# CC430F5123 register map
Registers are 16-bit, read-write, reset 0x0 unless marked. A register's access mark holds for its fields unless they carry their own. Offsets are from the block's base; [hi:lo] are bit positions; {n}, {i} and the like mark numbered series.

## Port_C
Base 0x00000000
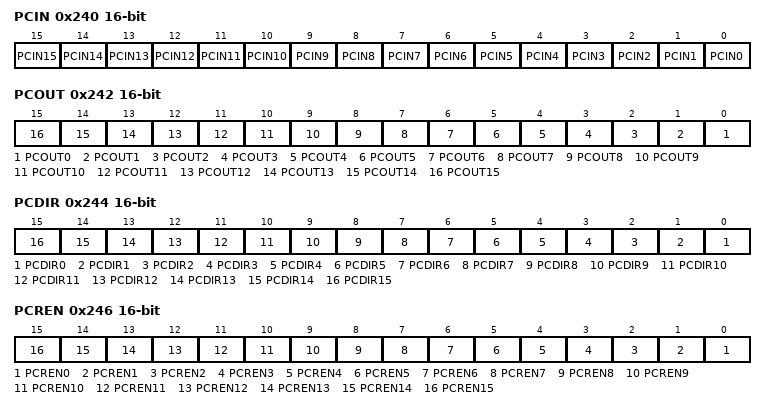
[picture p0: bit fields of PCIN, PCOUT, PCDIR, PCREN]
0x240 PCIN — Port C Input
  [n] PCIN{n} (n=0..15)
0x242 PCOUT — Port C Output
  [n] PCOUT{n} (n=0..15)
0x244 PCDIR — Port C Direction
  [n] PCDIR{n} (n=0..15)
0x246 PCREN — Port C Resistor Enable
  [n] PCREN{n} (n=0..15)
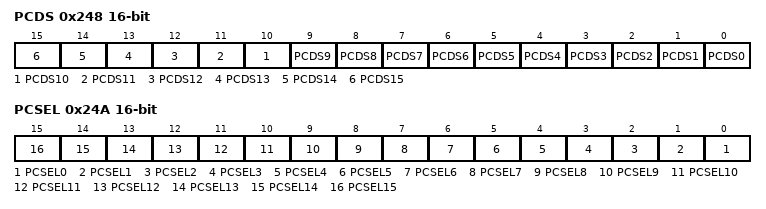
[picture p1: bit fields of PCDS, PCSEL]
0x248 PCDS — Port C Drive Strenght
  [n] PCDS{n} (n=0..15)
0x24A PCSEL — Port C Selection
  [n] PCSEL{n} (n=0..15)

## Port_5
Base 0x00000000
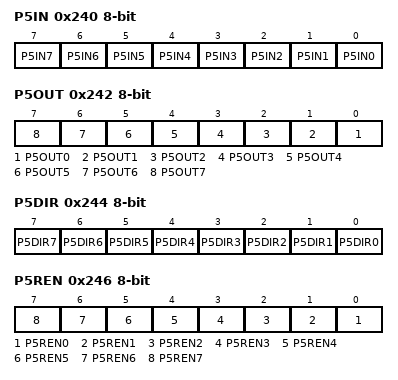
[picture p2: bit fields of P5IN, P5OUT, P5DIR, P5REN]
0x240 P5IN 8-bit — Port 5 Input
  [n] P5IN{n} (n=0..7)
0x242 P5OUT 8-bit — Port 5 Output
  [n] P5OUT{n} (n=0..7)
0x244 P5DIR 8-bit — Port 5 Direction
  [n] P5DIR{n} (n=0..7)
0x246 P5REN 8-bit — Port 5 Resistor Enable
  [n] P5REN{n} (n=0..7)
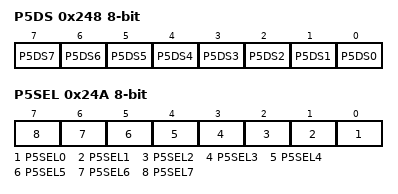
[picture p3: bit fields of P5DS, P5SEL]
0x248 P5DS 8-bit — Port 5 Drive Strenght
  [n] P5DS{n} (n=0..7)
0x24A P5SEL 8-bit — Port 5 Selection
  [n] P5SEL{n} (n=0..7)

## Port_J
Base 0x00000000
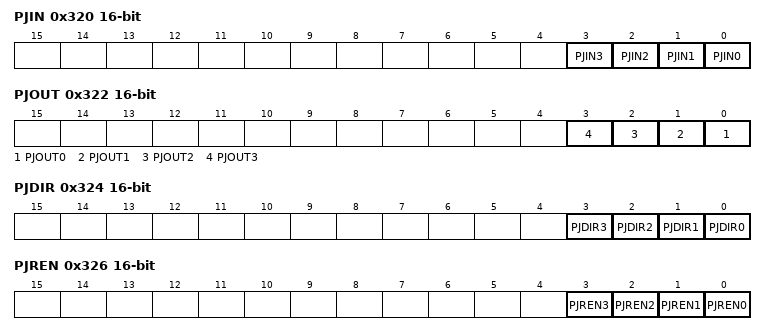
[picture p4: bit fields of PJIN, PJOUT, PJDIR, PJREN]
0x320 PJIN — Port J Input
  [n] PJIN{n} (n=0..3)
0x322 PJOUT — Port J Output
  [n] PJOUT{n} (n=0..3)
0x324 PJDIR — Port J Direction
  [n] PJDIR{n} (n=0..3)
0x326 PJREN — Port J Resistor Enable
  [n] PJREN{n} (n=0..3)
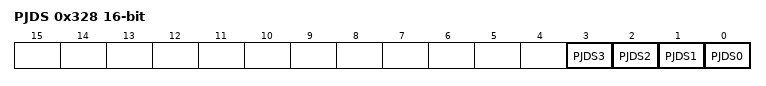
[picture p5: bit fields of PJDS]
0x328 PJDS — Port J Drive Strenght
  [n] PJDS{n} (n=0..3)

## Port_Mapping_Control
Base 0x00000000
0x1C0 PMAPKEYID — Port Mapping Key register
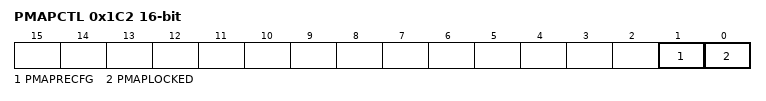
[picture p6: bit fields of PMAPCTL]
0x1C2 PMAPCTL — Port Mapping control register
  [1] PMAPRECFG — Port Mapping re-configuration control bit
  [0] PMAPLOCKED — Port Mapping Lock bit. Read only

## Port_Mapping_Port_1
Base 0x00000000
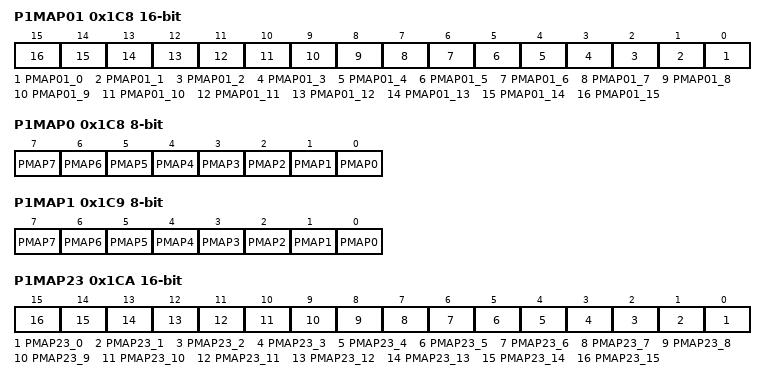
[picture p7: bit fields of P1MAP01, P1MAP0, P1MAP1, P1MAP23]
0x1C8 P1MAP01 — Port P1.0/1 mapping register
  [n] PMAP01_{n} (n=0..15)
0x1C8 P1MAP0 8-bit — Port P1.0 mapping register
  [n] PMAP{n} (n=0..7)
0x1C9 P1MAP1 8-bit — Port P1.1 mapping register
  [n] PMAP{n} (n=0..7)
0x1CA P1MAP23 — Port P1.2/3 mapping register
  [n] PMAP23_{n} (n=0..15)
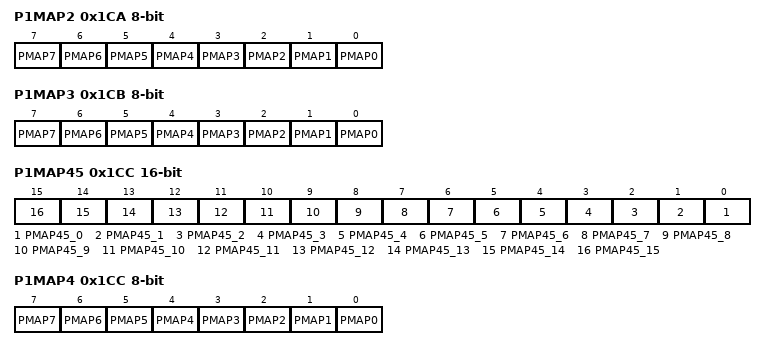
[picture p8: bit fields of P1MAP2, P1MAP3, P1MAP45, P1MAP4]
0x1CA P1MAP2 8-bit — Port P1.2 mapping register
  [n] PMAP{n} (n=0..7)
0x1CB P1MAP3 8-bit — Port P1.3 mapping register
  [n] PMAP{n} (n=0..7)
0x1CC P1MAP45 — Port P1.4/5 mapping register
  [n] PMAP45_{n} (n=0..15)
0x1CC P1MAP4 8-bit — Port P1.4 mapping register
  [n] PMAP{n} (n=0..7)
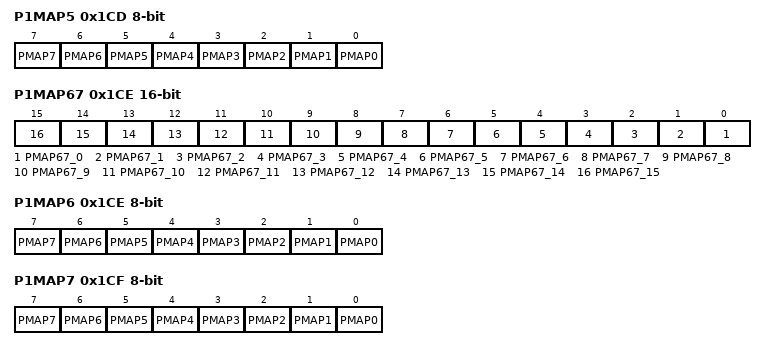
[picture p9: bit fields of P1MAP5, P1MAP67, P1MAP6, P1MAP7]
0x1CD P1MAP5 8-bit — Port P1.5 mapping register
  [n] PMAP{n} (n=0..7)
0x1CE P1MAP67 — Port P1.6/7 mapping register
  [n] PMAP67_{n} (n=0..15)
0x1CE P1MAP6 8-bit — Port P1.6 mapping register
  [n] PMAP{n} (n=0..7)
0x1CF P1MAP7 8-bit — Port P1.7 mapping register
  [n] PMAP{n} (n=0..7)

## Port_Mapping_Port_2
Base 0x00000000
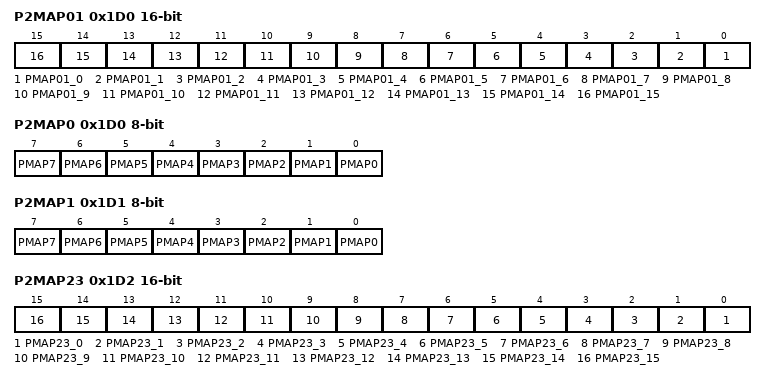
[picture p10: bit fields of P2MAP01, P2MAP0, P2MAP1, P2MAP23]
0x1D0 P2MAP01 — Port P2.0/1 mapping register
  [n] PMAP01_{n} (n=0..15)
0x1D0 P2MAP0 8-bit — Port P2.0 mapping register
  [n] PMAP{n} (n=0..7)
0x1D1 P2MAP1 8-bit — Port P2.1 mapping register
  [n] PMAP{n} (n=0..7)
0x1D2 P2MAP23 — Port P2.2/3 mapping register
  [n] PMAP23_{n} (n=0..15)
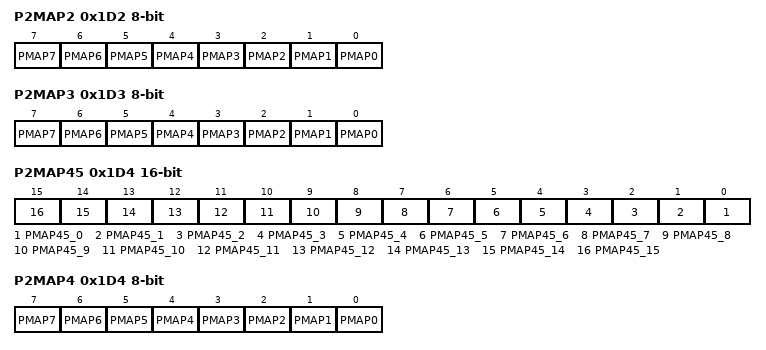
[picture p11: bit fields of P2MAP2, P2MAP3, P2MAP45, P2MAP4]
0x1D2 P2MAP2 8-bit — Port P2.2 mapping register
  [n] PMAP{n} (n=0..7)
0x1D3 P2MAP3 8-bit — Port P2.3 mapping register
  [n] PMAP{n} (n=0..7)
0x1D4 P2MAP45 — Port P2.4/5 mapping register
  [n] PMAP45_{n} (n=0..15)
0x1D4 P2MAP4 8-bit — Port P2.4 mapping register
  [n] PMAP{n} (n=0..7)
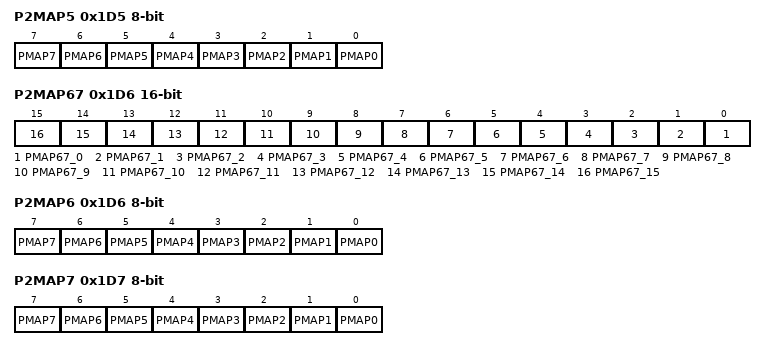
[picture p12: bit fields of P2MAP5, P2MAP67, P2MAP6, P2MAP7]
0x1D5 P2MAP5 8-bit — Port P2.5 mapping register
  [n] PMAP{n} (n=0..7)
0x1D6 P2MAP67 — Port P2.6/7 mapping register
  [n] PMAP67_{n} (n=0..15)
0x1D6 P2MAP6 8-bit — Port P2.6 mapping register
  [n] PMAP{n} (n=0..7)
0x1D7 P2MAP7 8-bit — Port P2.7 mapping register
  [n] PMAP{n} (n=0..7)

## Port_Mapping_Port_3
Base 0x00000000
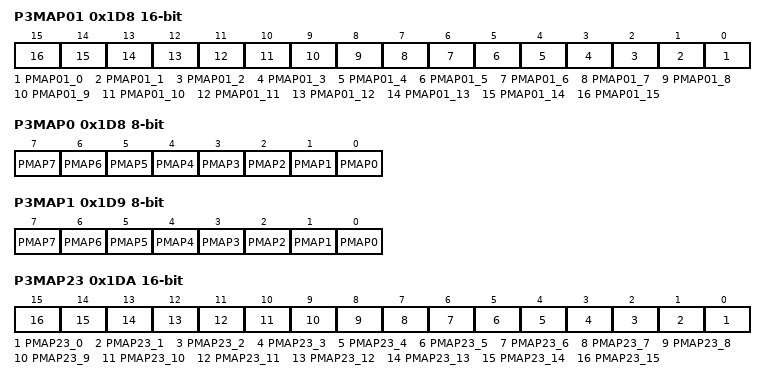
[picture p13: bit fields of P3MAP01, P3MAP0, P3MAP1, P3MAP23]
0x1D8 P3MAP01 — Port P3.0/1 mapping register
  [n] PMAP01_{n} (n=0..15)
0x1D8 P3MAP0 8-bit — Port P3.0 mapping register
  [n] PMAP{n} (n=0..7)
0x1D9 P3MAP1 8-bit — Port P3.1 mapping register
  [n] PMAP{n} (n=0..7)
0x1DA P3MAP23 — Port P3.2/3 mapping register
  [n] PMAP23_{n} (n=0..15)
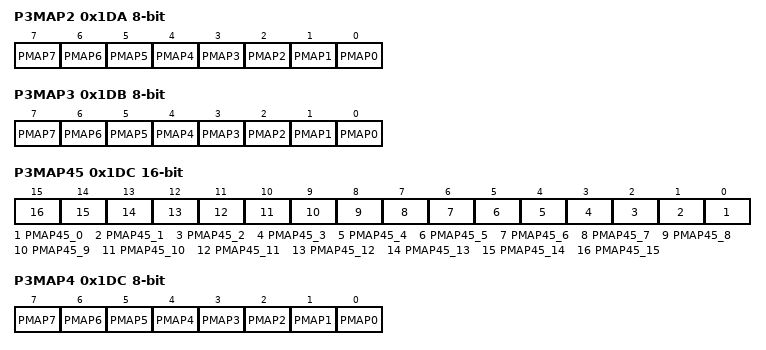
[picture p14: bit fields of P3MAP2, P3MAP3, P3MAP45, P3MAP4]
0x1DA P3MAP2 8-bit — Port P3.2 mapping register
  [n] PMAP{n} (n=0..7)
0x1DB P3MAP3 8-bit — Port P3.3 mapping register
  [n] PMAP{n} (n=0..7)
0x1DC P3MAP45 — Port P3.4/5 mapping register
  [n] PMAP45_{n} (n=0..15)
0x1DC P3MAP4 8-bit — Port P3.4 mapping register
  [n] PMAP{n} (n=0..7)
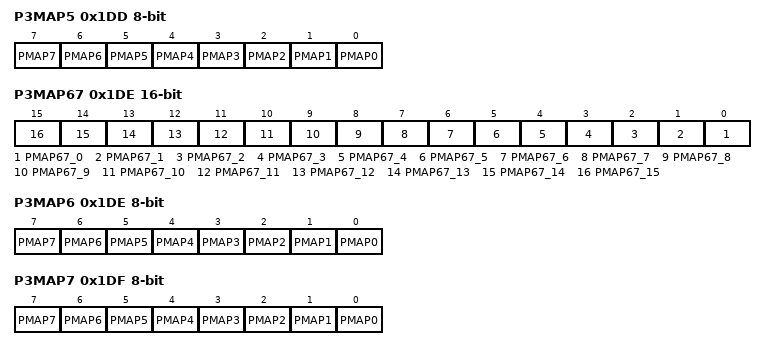
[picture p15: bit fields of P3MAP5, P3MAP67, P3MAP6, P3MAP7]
0x1DD P3MAP5 8-bit — Port P3.5 mapping register
  [n] PMAP{n} (n=0..7)
0x1DE P3MAP67 — Port P3.6/7 mapping register
  [n] PMAP67_{n} (n=0..15)
0x1DE P3MAP6 8-bit — Port P3.6 mapping register
  [n] PMAP{n} (n=0..7)
0x1DF P3MAP7 8-bit — Port P3.7 mapping register
  [n] PMAP{n} (n=0..7)
